VERSION ""

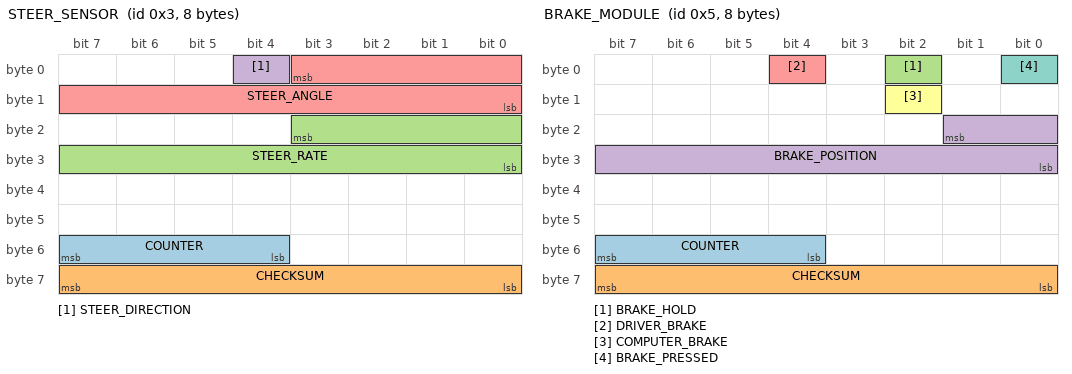
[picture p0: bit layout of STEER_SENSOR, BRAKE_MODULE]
BO_ 3 STEER_SENSOR: 8 XXX
 SG_ COUNTER : 55|4@0+ (1,0) [0|15] "" XXX
 SG_ CHECKSUM : 63|8@0+ (1,0) [0|255] "" XXX
 SG_ STEER_RATE : 19|12@0- (0.5,0) [0|255] "" XXX
 SG_ STEER_DIRECTION : 4|1@0+ (1,2) [0|1] "" XXX
 SG_ STEER_ANGLE : 3|12@0- (-0.5,0) [-500|500] "degrees" XXX

BO_ 5 BRAKE_MODULE: 8 XXX
 SG_ COUNTER : 55|4@0+ (1,0) [0|15] "" XXX
 SG_ CHECKSUM : 63|8@0+ (1,0) [0|255] "" XXX
 SG_ BRAKE_HOLD : 2|1@0+ (1,0) [0|1] "" XXX
 SG_ BRAKE_POSITION : 17|10@0+ (1,0) [0|65535] "" XXX
 SG_ DRIVER_BRAKE : 4|1@0+ (1,0) [0|1] "" XXX
 SG_ COMPUTER_BRAKE : 10|1@0+ (1,0) [0|1] "" XXX
 SG_ BRAKE_PRESSED : 0|1@1+ (1,0) [0|1] "" XXX

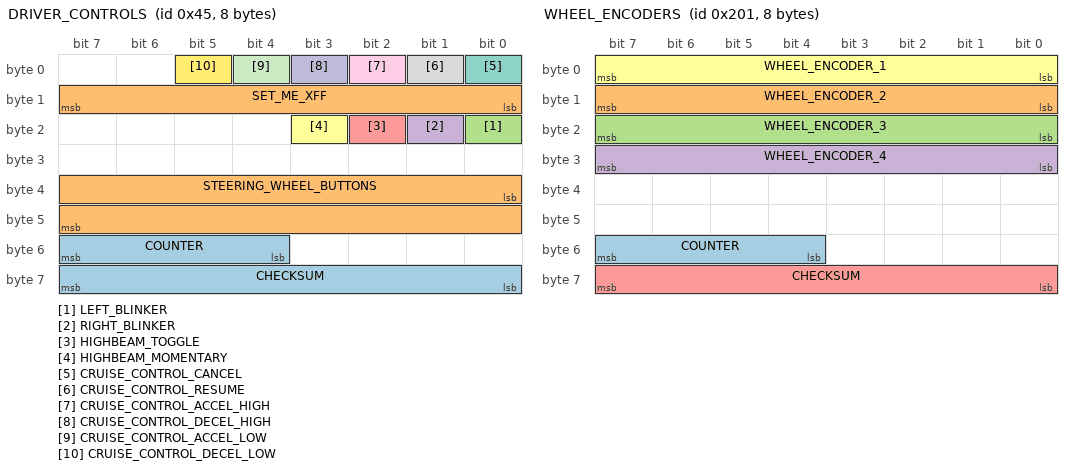
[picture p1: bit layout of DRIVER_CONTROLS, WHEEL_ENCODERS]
BO_ 69 DRIVER_CONTROLS: 8 XXX
 SG_ COUNTER : 55|4@0+ (1,0) [0|15] "" XXX
 SG_ STEERING_WHEEL_BUTTONS : 32|16@1+ (1,0) [0|255] "4 directional, 2 volume control & 2 phone buttons" XXX
 SG_ LEFT_BLINKER : 16|1@0+ (1,0) [0|1] "" XXX
 SG_ RIGHT_BLINKER : 17|1@0+ (1,0) [0|1] "" XXX
 SG_ HIGHBEAM_TOGGLE : 18|1@0+ (1,0) [0|1] "" XXX
 SG_ HIGHBEAM_MOMENTARY : 19|1@0+ (1,0) [0|1] "" XXX
 SG_ CRUISE_CONTROL_CANCEL : 0|1@0+ (1,0) [0|1] "" XXX
 SG_ CRUISE_CONTROL_RESUME : 1|1@0+ (1,0) [0|1] "" XXX
 SG_ CRUISE_CONTROL_ACCEL_HIGH : 2|1@0+ (1,0) [0|1] "" XXX
 SG_ CRUISE_CONTROL_DECEL_HIGH : 3|1@0+ (1,0) [0|1] "" XXX
 SG_ CRUISE_CONTROL_ACCEL_LOW : 4|1@0+ (1,0) [0|1] "" XXX
 SG_ CRUISE_CONTROL_DECEL_LOW : 5|1@0+ (1,0) [0|1] "" XXX
 SG_ CHECKSUM : 63|8@0+ (1,0) [0|255] "" XXX
 SG_ SET_ME_XFF : 15|8@0+ (1,0) [0|255] "" XXX

BO_ 513 WHEEL_ENCODERS: 8 XXX
 SG_ COUNTER : 55|4@0+ (1,0) [0|15] "" XXX
 SG_ WHEEL_ENCODER_2 : 15|8@0+ (1,0) [0|255] "" XXX
 SG_ WHEEL_ENCODER_3 : 23|8@0+ (1,0) [0|255] "" XXX
 SG_ WHEEL_ENCODER_4 : 31|8@0+ (1,0) [0|255] "" XXX
 SG_ CHECKSUM : 56|8@1+ (1,0) [0|255] "" XXX
 SG_ WHEEL_ENCODER_1 : 7|8@0+ (1,0) [0|255] "" XXX

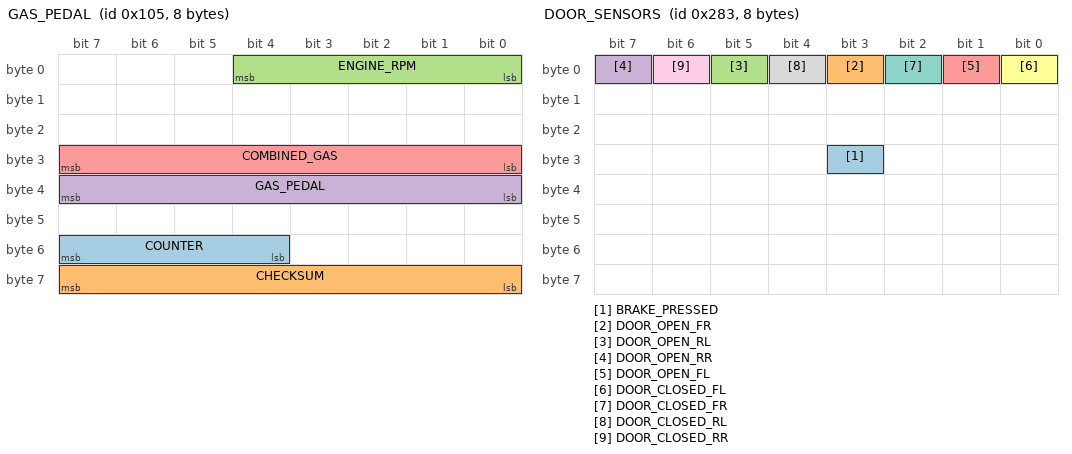
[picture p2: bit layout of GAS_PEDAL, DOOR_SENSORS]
BO_ 261 GAS_PEDAL: 8 XXX
 SG_ COUNTER : 55|4@0+ (1,0) [0|15] "" XXX
 SG_ CHECKSUM : 63|8@0+ (1,0) [0|255] "" XXX
 SG_ ENGINE_RPM : 4|5@0+ (1,0) [0|255] "" XXX
 SG_ GAS_PEDAL : 39|8@0+ (1,0) [0|255] "" XXX
 SG_ COMBINED_GAS : 31|8@0+ (1,0) [0|255] "" XXX

BO_ 643 DOOR_SENSORS: 8 XXX
 SG_ BRAKE_PRESSED : 27|1@0+ (1,0) [0|1] "" XXX
 SG_ DOOR_OPEN_FR : 3|1@1+ (1,0) [0|3] "" XXX
 SG_ DOOR_OPEN_RL : 5|1@0+ (1,0) [0|3] "" XXX
 SG_ DOOR_OPEN_RR : 7|1@0+ (1,0) [0|3] "" XXX
 SG_ DOOR_OPEN_FL : 1|1@0+ (1,0) [0|1] "" XXX
 SG_ DOOR_CLOSED_FL : 0|1@0+ (1,0) [0|1] "" XXX
 SG_ DOOR_CLOSED_FR : 2|1@0+ (1,0) [0|1] "" XXX
 SG_ DOOR_CLOSED_RL : 4|1@0+ (1,0) [0|1] "" XXX
 SG_ DOOR_CLOSED_RR : 6|1@0+ (1,0) [0|1] "" XXX

BO_ 885 SEATBELT_SENSORS: 8 XXX
 SG_ SEATBELT_DRIVER_LATCHED : 16|1@0+ (1,0) [0|1] "" XXX
 SG_ SEATBELT_PASSENGER_LATCHED : 18|1@0+ (1,0) [0|1] "" XXX

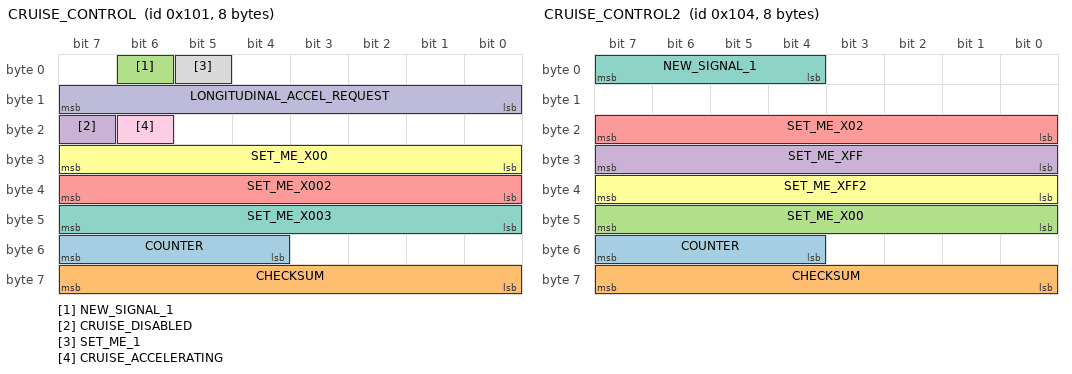
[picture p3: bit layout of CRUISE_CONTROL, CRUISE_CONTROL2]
BO_ 257 CRUISE_CONTROL: 8 XXX
 SG_ COUNTER : 55|4@0+ (1,0) [0|15] "" XXX
 SG_ CHECKSUM : 63|8@0+ (1,0) [0|255] "" XXX
 SG_ NEW_SIGNAL_1 : 6|1@0+ (1,0) [0|255] "" XXX
 SG_ CRUISE_DISABLED : 23|1@0+ (1,0) [0|1] "" XXX
 SG_ SET_ME_X002 : 39|8@0+ (1,0) [0|255] "" XXX
 SG_ SET_ME_X00 : 31|8@0+ (1,0) [0|255] "" XXX
 SG_ SET_ME_X003 : 47|8@0+ (1,0) [0|255] "" XXX
 SG_ SET_ME_1 : 5|1@0+ (1,0) [0|1] "" XXX
 SG_ CRUISE_ACCELERATING : 22|1@0+ (1,0) [0|1] "" XXX
 SG_ LONGITUDINAL_ACCEL_REQUEST : 15|8@0- (1,0) [0|127] "" XXX

BO_ 260 CRUISE_CONTROL2: 8 XXX
 SG_ COUNTER : 55|4@0+ (1,0) [0|15] "" XXX
 SG_ CHECKSUM : 63|8@0+ (1,0) [0|255] "" XXX
 SG_ SET_ME_X00 : 47|8@0+ (1,0) [0|255] "" XXX
 SG_ SET_ME_XFF : 31|8@0+ (1,0) [0|65535] "" XXX
 SG_ SET_ME_X02 : 23|8@0+ (1,0) [0|255] "" XXX
 SG_ SET_ME_XFF2 : 39|8@0+ (1,0) [0|255] "" XXX
 SG_ NEW_SIGNAL_1 : 7|4@0+ (1,0) [0|255] "" XXX

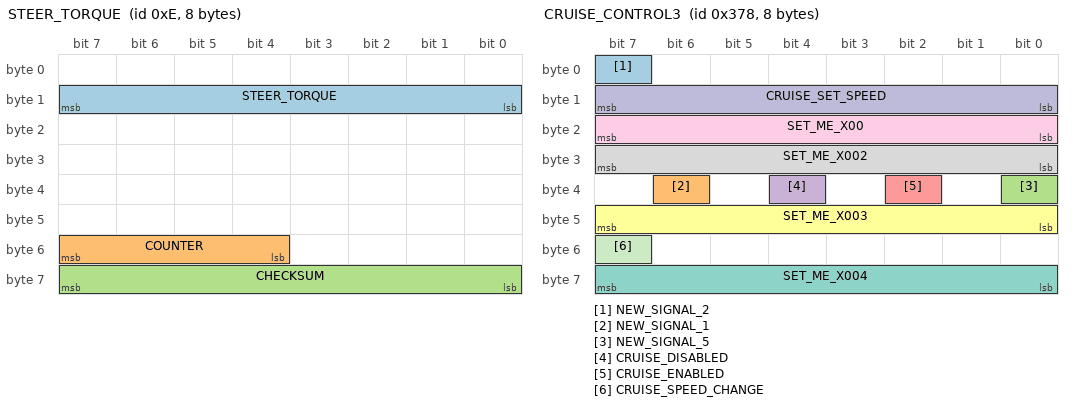
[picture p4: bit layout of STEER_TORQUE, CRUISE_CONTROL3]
BO_ 14 STEER_TORQUE: 8 XXX
 SG_ STEER_TORQUE : 15|8@0+ (1,0) [0|255] "" XXX
 SG_ COUNTER : 55|4@0+ (1,0) [0|15] "" XXX
 SG_ CHECKSUM : 63|8@0+ (1,0) [0|255] "" XXX

BO_ 888 CRUISE_CONTROL3: 8 XXX
 SG_ NEW_SIGNAL_2 : 7|1@0+ (1,0) [0|1] "" XXX
 SG_ NEW_SIGNAL_1 : 38|1@0+ (1,0) [0|1] "" XXX
 SG_ NEW_SIGNAL_5 : 32|1@0+ (1,0) [0|1] "" XXX
 SG_ CRUISE_DISABLED : 36|1@0+ (1,0) [0|1] "" XXX
 SG_ CRUISE_ENABLED : 34|1@0+ (1,0) [0|1] "" XXX
 SG_ SET_ME_X003 : 47|8@0+ (1,0) [0|255] "" XXX
 SG_ SET_ME_X004 : 63|8@0+ (1,0) [0|255] "" XXX
 SG_ SET_ME_X002 : 31|8@0+ (1,0) [0|255] "" XXX
 SG_ SET_ME_X00 : 23|8@0+ (1,0) [0|255] "" XXX
 SG_ CRUISE_SET_SPEED : 15|8@0+ (1,0) [0|63] "mph" XXX
 SG_ CRUISE_SPEED_CHANGE : 55|1@0+ (1,0) [0|1] "" XXX

BO_ 307 POWER_SEATS: 8 XXX
 SG_ DRIVER_FORWARD : 0|1@0+ (1,0) [0|1] "" XXX
 SG_ DRIVER_BACK : 1|1@0+ (1,0) [0|1] "" XXX

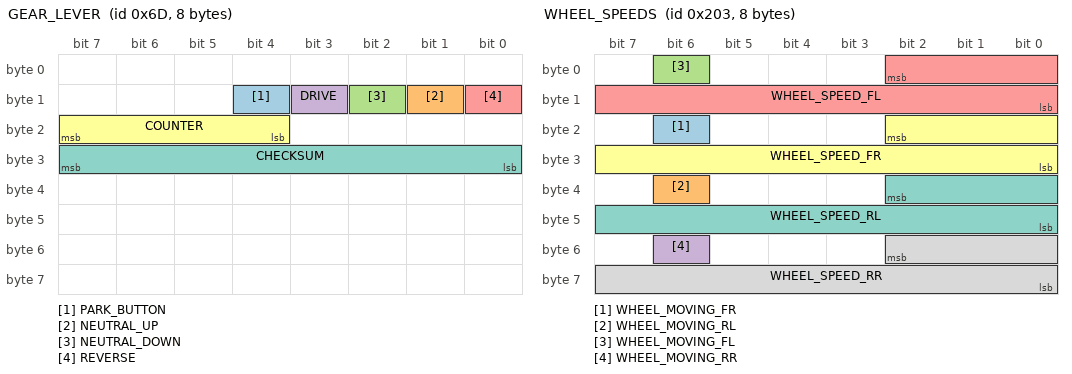
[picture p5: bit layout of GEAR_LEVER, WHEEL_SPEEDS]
BO_ 109 GEAR_LEVER: 8 XXX
 SG_ PARK_BUTTON : 12|1@0+ (1,0) [0|1] "" XXX
 SG_ NEUTRAL_UP : 9|1@0+ (1,0) [0|1] "" XXX
 SG_ NEUTRAL_DOWN : 10|1@0+ (1,0) [0|1] "" XXX
 SG_ DRIVE : 11|1@0+ (1,0) [0|1] "" XXX
 SG_ REVERSE : 8|1@0+ (1,0) [0|1] "" XXX
 SG_ COUNTER : 23|4@0+ (1,0) [0|15] "" XXX
 SG_ CHECKSUM : 31|8@0+ (1,0) [0|255] "" XXX

BO_ 115 GEAR_PACKET: 8 XXX
 SG_ GEAR : 0|4@1+ (1,0) [0|15] "" XXX

BO_ 581 IGNITION: 8 XXX

BO_ 515 WHEEL_SPEEDS: 8 XXX
 SG_ WHEEL_MOVING_FR : 22|1@1+ (1,0) [0|15] "" XXX
 SG_ WHEEL_MOVING_RL : 38|1@0+ (1,0) [0|1] "" XXX
 SG_ WHEEL_MOVING_FL : 6|1@0+ (1,0) [0|1] "" XXX
 SG_ WHEEL_MOVING_RR : 54|1@0+ (1,0) [0|1] "" XXX
 SG_ WHEEL_SPEED_FL : 2|11@0+ (0.0375,0) [0|255] "mph" XXX
 SG_ WHEEL_SPEED_FR : 18|11@0+ (0.0375,0) [0|255] "mph" XXX
 SG_ WHEEL_SPEED_RL : 34|11@0+ (0.0375,0) [0|255] "mph" XXX
 SG_ WHEEL_SPEED_RR : 50|11@0+ (0.0375,0) [0|255] "mph" XXX

BU_: IAP ODS _4WD BCM HUD DATC MDPS AAF_Tester AEMC SMK _4WD EPB CUBIS MTS TMU EVP CGW TPMS LPI DI_BOX SPAS EMS LCA TCU IBOX FATC AFLS FPCM SCC AHLS AVM ABS SNV OPI PGS SAS AAF Dummy LDWS_LKAS LVR ESC PSB CLU ECS ACU REA

CM_ "AUTOGENERATED FILE, DO NOT EDIT";

CM_ "hyundai_kia_mando_front_radar.dbc starts here";

VAL_ 34 IPMA_PCAN_DataRangeCheck 1 "Fault Present" 0 "No Fault";
VAL_ 34 IPMA_PCAN_MissingMsg 1 "Fault Present" 0 "No Fault ";
VAL_ 34 VINSignalCompareFailure 1 "Fault Present" 0 "No Fault";
VAL_ 34 ModuleNotConfiguredError 1 "Fault Present" 0 "No Fault";
VAL_ 34 CarCfgNotConfiguredError 1 "Fault Present" 0 "No Fault";
VAL_ 33 Active_Flt_Latched_byte7_bit7 1 "Fault Present" 0 "No Fault";
VAL_ 33 Active_Flt_Latched_byte7_bit6 1 "Fault Present" 0 "No Fault";
VAL_ 33 Active_Flt_Latched_byte7_bit5 1 "Fault Present" 0 "No Fault";
VAL_ 33 Active_Flt_Latched_byte7_bit4 1 "Fault Present" 0 "No Fault";
VAL_ 33 ARMtoDSPChksumFault 1 "Fault Present" 0 "No Fault";
VAL_ 33 DSPtoArmChksumFault 1 "Fault Present" 0 "No Fault";
VAL_ 33 HostToArmChksumFault 1 "Fault Present" 0 "No Fault";
VAL_ 33 ARMtoHostChksumFault 1 "Fault Present" 0 "No Fault";
VAL_ 33 LoopBWOutOfRange 1 "Fault Present" 0 "No Fault";
VAL_ 33 DSPOverrunFault 1 "Fault Present" 0 "No Fault";
VAL_ 33 Active_Flt_Latched_byte6_bit5 1 "Fault Present" 0 "No Fault";
VAL_ 33 TuningSensitivityFault 1 "Fault Present" 0 "No Fault";
VAL_ 33 SaturatedTuningFreqFault 1 "Fault Present" 0 "No Fault";
VAL_ 33 LocalOscPowerFault 1 "Fault Present" 0 "No Fault";
VAL_ 33 TransmitterPowerFault 1 "Fault Present" 0 "No Fault";
VAL_ 33 Active_Flt_Latched_byte6_bit0 1 "Fault Present" 0 "No Fault";
VAL_ 33 Active_Flt_Latched_byte5_bit7 1 "Fault Present" 0 "No Fault";
VAL_ 33 Active_Flt_Latched_byte5_bit6 1 "Fault Present" 0 "No Fault";
VAL_ 33 XCVRDeviceSPIFault 1 "Fault Present" 0 "No Fault";
VAL_ 33 FreqSynthesizerSPIFault 1 "Fault Present" 0 "No Fault";
VAL_ 33 AnalogConverterDevicSPIFault 1 "Fault Present" 0 "No Fault";
VAL_ 33 SidelobeBlockage 1 "Fault Present" 0 "No Fault";
VAL_ 33 Active_Flt_Latched_byte5_bit1 1 "Fault Present" 0 "No Fault";
VAL_ 33 MNRBlocked 1 "Fault Present" 0 "No Fault";
VAL_ 33 ECUTempHighFault 1 "Fault Present" 0 "No Fault";
VAL_ 33 TransmitterTempHighFault 1 "Fault Present" 0 "No Fault";
VAL_ 33 AlignmentRoutineFailedFault 1 "Fault Present" 0 "No Fault";
VAL_ 33 UnreasonableRadarData 1 "Fault Present" 0 "No Fault";
VAL_ 33 MicroprocessorTempHighFault 1 "Fault Present" 0 "No Fault";
VAL_ 33 VerticalAlignmentOutOfRange 1 "Fault Present" 0 "No Fault";
VAL_ 33 HorizontalAlignmentOutOfRange 1 "Fault Present" 0 "No Fault";
VAL_ 33 FactoryAlignmentMode 1 "Fault Present" 0 "No Fault";
VAL_ 33 BatteryLowFault 1 "Fault Present" 0 "No Fault";
VAL_ 33 BatteryHighFault 1 "Fault Present" 0 "No Fault";
VAL_ 33 v_1p25SupplyOutOfRange 1 "Fault Present" 0 "No Fault";
VAL_ 33 Active_Flt_Latched_byte3_bit4 1 "Fault Present" 0 "No Fault";
VAL_ 33 ThermistorOutOfRange 1 "Fault Present" 0 "No Fault";
VAL_ 33 v_3p3DACSupplyOutOfRange 1 "Fault Present" 0 "No Fault";
VAL_ 33 v_3p3RAWSupplyOutOfRange 1 "Fault Present" 0 "No Fault";
VAL_ 33 v_5_SupplyOutOfRange 1 "Fault Present" 0 "No Fault";
VAL_ 33 TransmitterIDFault 1 "Fault Present" 0 "No Fault";
VAL_ 33 Active_Flt_Latched_byte2_bit6 1 "Fault Present" 0 "No Fault";
VAL_ 33 Active_Flt_Latched_byte2_bit5 1 "Fault Present" 0 "No Fault";
VAL_ 33 Active_Flt_Latched_byte2_bit4 1 "Fault Present" 0 "No Fault";
VAL_ 33 Active_Flt_Latched_byte2_bit3 1 "Fault Present" 0 "No Fault";
VAL_ 33 Active_Flt_Latched_byte2_bit2 1 "Fault Present" 0 "No Fault";
VAL_ 33 PCANMissingMsgFault 1 "Fault Present" 0 "No Fault";
VAL_ 33 PCANBusOff 1 "Fault Present" 0 "No Fault";
VAL_ 33 Active_Flt_Latched_byte1_bit7 1 "Fault Present" 0 "No Fault";
VAL_ 33 Active_Flt_Latched_byte1_bit6 1 "Fault Present" 0 "No Fault";
VAL_ 33 InstructionSetCheckFault 1 "Fault Present" 0 "No Fault";
VAL_ 33 StackOverflowFault 1 "Fault Present" 0 "No Fault";
VAL_ 33 WatchdogFault 1 "Fault Present" 0 "No Fault";
VAL_ 33 PLLLockFault 1 "Fault Present" 0 "No Fault";
VAL_ 33 Active_Flt_Latched_byte1_bit1 1 "Fault Present" 0 "No Fault";
VAL_ 33 RAMMemoryTestFault 1 "Fault Present" 0 "No Fault";
VAL_ 33 USCValidationFault 1 "Fault Present" 0 "No Fault";
VAL_ 33 Active_Flt_Latched_byte0_bit6 1 "Fault Present" 0 "No Fault";
VAL_ 33 Active_Flt_Latched_byte0_bit5 1 "Fault Present" 0 "No Fault";
VAL_ 33 Active_Flt_Latched_byte0_bit4 1 "Fault Present" 0 "No Fault";
VAL_ 33 Active_Flt_Latched_byte0_bit3 1 "Fault Present" 0 "No Fault";
VAL_ 33 KeepAliveChecksumFault 1 "Fault Present" 0 "No Fault";
VAL_ 33 ProgramCalibrationFlashChecksum 1 "Fault Present" 0 "No Fault";
VAL_ 33 ApplicationFlashChecksumFault 1 "Fault Present" 0 "No Fault";
VAL_ 371 CAN_AUTO_ALIGN_HANGLE_QF 3 "Accurate" 2 "Innacurate" 1 "Temporarily undefined" 0 "Undefined";
VAL_ 371 CAN_ALIGNMENT_STATUS 15 "Undefined_2" 14 "Undefined_1" 13 "Low Amplitude (Flat-plate only)" 12 "No Peak (Flat-plate only)" 11 "Fail Ver and Hor OutOfRange" 10 "Fail Vertical Align OutOfRange" 9 "Fail Horizontal Align OutOfRange" 8 "Fail Time Out" 7 "Fail Only Right Target Found" 6 "Fail Only Left Target Found" 5 "Fail Variance Too Large" 4 "Fail Deviation Too Large" 3 "Fail No Target" 2 "Success" 1 "Busy" 0 "Off";
VAL_ 371 CAN_ALIGNMENT_STATE 6 "Static alignment flat-plate" 5 "Static alignment 2-target" 4 "Static alignment 1-target" 3 "Service alignment" 2 "Short track alignment" 1 "Auto alignment" 0 "Off";
VAL_ 291 CAN_DET_CONFID_AZIMUTH_04 3 "Low" 2 "Medium_Low" 1 "Medium_High" 0 "High";
VAL_ 351 CAN_DET_CONFID_AZIMUTH_64 3 "Low" 2 "Medium_Low" 1 "Medium_High" 0 "High";
VAL_ 350 CAN_DET_CONFID_AZIMUTH_63 3 "Low" 2 "Medium_Low" 1 "Medium_High" 0 "High";
VAL_ 349 CAN_DET_CONFID_AZIMUTH_62 3 "Low" 2 "Medium_Low" 1 "Medium_High" 0 "High";
VAL_ 348 CAN_DET_CONFID_AZIMUTH_61 3 "Low" 2 "Medium_Low" 1 "Medium_High" 0 "High";
VAL_ 347 CAN_DET_CONFID_AZIMUTH_60 3 "Low" 2 "Medium_Low" 1 "Medium_High" 0 "High";
VAL_ 346 CAN_DET_CONFID_AZIMUTH_59 3 "Low" 2 "Medium_Low" 1 "Medium_High" 0 "High";
VAL_ 345 CAN_DET_CONFID_AZIMUTH_58 3 "Low" 2 "Medium_Low" 1 "Medium_High" 0 "High";
VAL_ 344 CAN_DET_CONFID_AZIMUTH_57 3 "Low" 2 "Medium_Low" 1 "Medium_High" 0 "High";
VAL_ 343 CAN_DET_CONFID_AZIMUTH_56 3 "Low" 2 "Medium_Low" 1 "Medium_High" 0 "High";
VAL_ 342 CAN_DET_CONFID_AZIMUTH_55 3 "Low" 2 "Medium_Low" 1 "Medium_High" 0 "High";
VAL_ 335 CAN_DET_CONFID_AZIMUTH_48 3 "Low" 2 "Medium_Low" 1 "Medium_High" 0 "High";
VAL_ 334 CAN_DET_CONFID_AZIMUTH_47 3 "Low" 2 "Medium_Low" 1 "Medium_High" 0 "High";
VAL_ 333 CAN_DET_CONFID_AZIMUTH_46 3 "Low" 2 "Medium_Low" 1 "Medium_High" 0 "High";
VAL_ 332 CAN_DET_CONFID_AZIMUTH_45 3 "Low" 2 "Medium_Low" 1 "Medium_High" 0 "High";
VAL_ 331 CAN_DET_CONFID_AZIMUTH_44 3 "Low" 2 "Medium_Low" 1 "Medium_High" 0 "High";
VAL_ 330 CAN_DET_CONFID_AZIMUTH_43 3 "Low" 2 "Medium_Low" 1 "Medium_High" 0 "High";
VAL_ 329 CAN_DET_CONFID_AZIMUTH_42 3 "Low" 2 "Medium_Low" 1 "Medium_High" 0 "High";
VAL_ 328 CAN_DET_CONFID_AZIMUTH_41 3 "Low" 2 "Medium_Low" 1 "Medium_High" 0 "High";
VAL_ 327 CAN_DET_CONFID_AZIMUTH_40 3 "Low" 2 "Medium_Low" 1 "Medium_High" 0 "High";
VAL_ 325 CAN_DET_CONFID_AZIMUTH_38 3 "Low" 2 "Medium_Low" 1 "Medium_High" 0 "High";
VAL_ 324 CAN_DET_CONFID_AZIMUTH_37 3 "Low" 2 "Medium_Low" 1 "Medium_High" 0 "High";
VAL_ 323 CAN_DET_CONFID_AZIMUTH_36 3 "Low" 2 "Medium_Low" 1 "Medium_High" 0 "High";
VAL_ 322 CAN_DET_CONFID_AZIMUTH_35 3 "Low" 2 "Medium_Low" 1 "Medium_High" 0 "High";
VAL_ 321 CAN_DET_CONFID_AZIMUTH_34 3 "Low" 2 "Medium_Low" 1 "Medium_High" 0 "High";
VAL_ 320 CAN_DET_CONFID_AZIMUTH_33 3 "Low" 2 "Medium_Low" 1 "Medium_High" 0 "High";
VAL_ 319 CAN_DET_CONFID_AZIMUTH_32 3 "Low" 2 "Medium_Low" 1 "Medium_High" 0 "High";
VAL_ 318 CAN_DET_CONFID_AZIMUTH_31 3 "Low" 2 "Medium_Low" 1 "Medium_High" 0 "High";
VAL_ 317 CAN_DET_CONFID_AZIMUTH_30 3 "Low" 2 "Medium_Low" 1 "Medium_High" 0 "High";
VAL_ 316 CAN_DET_CONFID_AZIMUTH_29 3 "Low" 2 "Medium_Low" 1 "Medium_High" 0 "High";
VAL_ 314 CAN_DET_CONFID_AZIMUTH_27 3 "Low" 2 "Medium_Low" 1 "Medium_High" 0 "High";
VAL_ 313 CAN_DET_CONFID_AZIMUTH_26 3 "Low" 2 "Medium_Low" 1 "Medium_High" 0 "High";
VAL_ 312 CAN_DET_CONFID_AZIMUTH_25 3 "Low" 2 "Medium_Low" 1 "Medium_High" 0 "High";
VAL_ 311 CAN_DET_CONFID_AZIMUTH_24 3 "Low" 2 "Medium_Low" 1 "Medium_High" 0 "High";
VAL_ 310 CAN_DET_CONFID_AZIMUTH_23 3 "Low" 2 "Medium_Low" 1 "Medium_High" 0 "High";
VAL_ 309 CAN_DET_CONFID_AZIMUTH_22 3 "Low" 2 "Medium_Low" 1 "Medium_High" 0 "High";
VAL_ 308 CAN_DET_CONFID_AZIMUTH_21 3 "Low" 2 "Medium_Low" 1 "Medium_High" 0 "High";
VAL_ 307 CAN_DET_CONFID_AZIMUTH_20 3 "Low" 2 "Medium_Low" 1 "Medium_High" 0 "High";
VAL_ 306 CAN_DET_CONFID_AZIMUTH_19 3 "Low" 2 "Medium_Low" 1 "Medium_High" 0 "High";
VAL_ 305 CAN_DET_CONFID_AZIMUTH_18 3 "Low" 2 "Medium_Low" 1 "Medium_High" 0 "High";
VAL_ 341 CAN_DET_CONFID_AZIMUTH_54 3 "Low" 2 "Medium_Low" 1 "Medium_High" 0 "High";
VAL_ 340 CAN_DET_CONFID_AZIMUTH_53 3 "Low" 2 "Medium_Low" 1 "Medium_High" 0 "High";
VAL_ 339 CAN_DET_CONFID_AZIMUTH_52 3 "Low" 2 "Medium_Low" 1 "Medium_High" 0 "High";
VAL_ 338 CAN_DET_CONFID_AZIMUTH_51 3 "Low" 2 "Medium_Low" 1 "Medium_High" 0 "High";
VAL_ 337 CAN_DET_CONFID_AZIMUTH_50 3 "Low" 2 "Medium_Low" 1 "Medium_High" 0 "High";
VAL_ 336 CAN_DET_CONFID_AZIMUTH_49 3 "Low" 2 "Medium_Low" 1 "Medium_High" 0 "High";
VAL_ 326 CAN_DET_CONFID_AZIMUTH_39 3 "Low" 2 "Medium_Low" 1 "Medium_High" 0 "High";
VAL_ 315 CAN_DET_CONFID_AZIMUTH_28 3 "Low" 2 "Medium_Low" 1 "Medium_High" 0 "High";
VAL_ 304 CAN_DET_CONFID_AZIMUTH_17 3 "Low" 2 "Medium_Low" 1 "Medium_High" 0 "High";
VAL_ 303 CAN_DET_CONFID_AZIMUTH_16 3 "Low" 2 "Medium_Low" 1 "Medium_High" 0 "High";
VAL_ 302 CAN_DET_CONFID_AZIMUTH_15 3 "Low" 2 "Medium_Low" 1 "Medium_High" 0 "High";
VAL_ 301 CAN_DET_CONFID_AZIMUTH_14 3 "Low" 2 "Medium_Low" 1 "Medium_High" 0 "High";
VAL_ 300 CAN_DET_CONFID_AZIMUTH_13 3 "Low" 2 "Medium_Low" 1 "Medium_High" 0 "High";
VAL_ 299 CAN_DET_CONFID_AZIMUTH_12 3 "Low" 2 "Medium_Low" 1 "Medium_High" 0 "High";
VAL_ 298 CAN_DET_CONFID_AZIMUTH_11 3 "Low" 2 "Medium_Low" 1 "Medium_High" 0 "High";
VAL_ 297 CAN_DET_CONFID_AZIMUTH_10 3 "Low" 2 "Medium_Low" 1 "Medium_High" 0 "High";
VAL_ 296 CAN_DET_CONFID_AZIMUTH_09 3 "Low" 2 "Medium_Low" 1 "Medium_High" 0 "High";
VAL_ 295 CAN_DET_CONFID_AZIMUTH_08 3 "Low" 2 "Medium_Low" 1 "Medium_High" 0 "High";
VAL_ 294 CAN_DET_CONFID_AZIMUTH_07 3 "Low" 2 "Medium_Low" 1 "Medium_High" 0 "High";
VAL_ 293 CAN_DET_CONFID_AZIMUTH_06 3 "Low" 2 "Medium_Low" 1 "Medium_High" 0 "High";
VAL_ 292 CAN_DET_CONFID_AZIMUTH_05 3 "Low" 2 "Medium_Low" 1 "Medium_High" 0 "High";
VAL_ 290 CAN_DET_CONFID_AZIMUTH_03 3 "Low" 2 "Medium_Low" 1 "Medium_High" 0 "High";
VAL_ 289 CAN_DET_CONFID_AZIMUTH_02 3 "Low" 2 "Medium_Low" 1 "Medium_High" 0 "High";
VAL_ 257 CAN_INTERFERENCE_TYPE 2 "Star PD-Like" 1 "Slow FMCW" 0 "No Interference";
VAL_ 257 CAN_RECOMMEND_UNCONVERGE 1 "Recommended" 0 "Not Recommended";
VAL_ 257 CAN_RADAR_ALIGN_INCOMPLETE 1 "Alignment Incomplete" 0 "Alignment Completed";
VAL_ 257 CAN_BLOCKAGE_SIDELOBE 1 "Radar Blockage" 0 "No Radar Blockage";
VAL_ 257 CAN_BLOCKAGE_MNR 1 "Radar Blockage" 0 "No Radar Blockage";
VAL_ 257 CAN_RADAR_EXT_COND_NOK 1 "Too high temp or insufficient pw" 0 "External conditions OK";
VAL_ 257 CAN_RADAR_ALIGN_OUT_RANGE 1 "Radar out of range" 0 "Radar within range";
VAL_ 257 CAN_RADAR_ALIGN_NOT_START 1 "Radar align not started" 0 "Radar align started";
VAL_ 257 CAN_RADAR_OVERHEAT_ERROR 1 "Radar overheat condition" 0 "No Overheat";
VAL_ 257 CAN_RADAR_NOT_OP 1 "Radar not operational" 0 "Radar operational";
VAL_ 257 CAN_XCVR_OPERATIONAL 1 "On" 0 "Off ";
